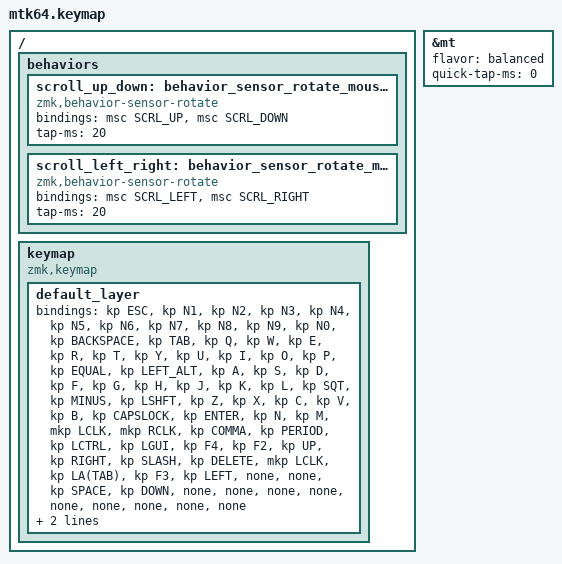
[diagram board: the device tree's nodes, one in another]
#include <behaviors.dtsi>
#include <dt-bindings/zmk/keys.h>
#include <dt-bindings/zmk/pointing.h>
#include "keycode_japanese.h"

// スクロール量の設定

#define ZMK_POINTING_DEFAULT_SCRL_VAL 100

&mt {
    flavor = "balanced";
    quick-tap-ms = <0>;
};

/ {
    behaviors {
        // 垂直スクロール用のbehaviorの設定

        scroll_up_down: behavior_sensor_rotate_mouse_wheel_up_down {
            compatible = "zmk,behavior-sensor-rotate";
            #sensor-binding-cells = <0>;
            bindings = <&msc SCRL_UP>, <&msc SCRL_DOWN>;

            tap-ms = <20>; // スクロールのタップ時間
        };

        // 水平スクロール用のbehaviorの設定

        scroll_left_right: behavior_sensor_rotate_mouse_wheel_left_right {
            compatible = "zmk,behavior-sensor-rotate";
            #sensor-binding-cells = <0>;
            bindings = <&msc SCRL_LEFT>, <&msc SCRL_RIGHT>;

            tap-ms = <20>; // スクロールのタップ時間
        };
    };
};

/ {
    keymap {
        compatible = "zmk,keymap";

        default_layer {
            bindings = <
&kp ESC  &kp N1  &kp N2  &kp N3  &kp N4  &kp N5  &kp N6  &kp N7  &kp N8  &kp N9  &kp N0  &kp BACKSPACE  &kp TAB  &kp Q  &kp W  &kp E  &kp R  &kp T  &kp Y  &kp U  &kp I  &kp O  &kp P  &kp EQUAL  &kp LEFT_ALT  &kp A  &kp S  &kp D  &kp F  &kp G  &kp H  &kp J  &kp K  &kp L  &kp SQT  &kp MINUS  &kp LSHFT  &kp Z  &kp X  &kp C  &kp V  &kp B  &kp CAPSLOCK  &kp ENTER  &kp N  &kp M  &mkp LCLK  &mkp RCLK  &kp COMMA  &kp PERIOD  &kp LCTRL  &kp LGUI  &kp F4  &kp F2  &kp UP  &kp RIGHT  &kp SLASH  &kp DELETE  &mkp LCLK  &kp LA(TAB)  &kp F3  &kp LEFT  &none  &none  &kp SPACE  &kp DOWN  &none  &none  &none  &none  &none  &none  &none  &none  &none
            >;

            sensor-bindings = <&inc_dec_kp LEFT RIGHT>, <&scroll_up_down>;
        };
    };
};
